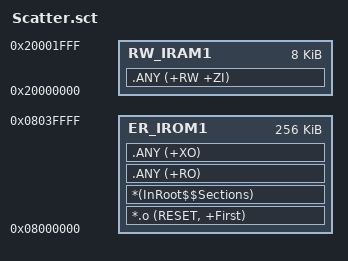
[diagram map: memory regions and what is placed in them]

LR_IROM1 0x8000000 0x40000  {    ; load region size_region
  ER_IROM1 0x8000000 0x40000  {  ; load address = execution address
   *.o (RESET, +First)
   *(InRoot$$Sections)
   .ANY (+RO)
   .ANY (+XO)
  }
  RW_IRAM1 0x20000000 0x2000  {  ; RW data
   .ANY (+RW +ZI)
  }
}
